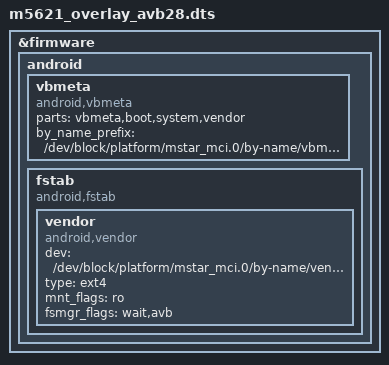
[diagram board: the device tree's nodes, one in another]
/dts-v1/;
/plugin/;

&firmware {
	android {
		vbmeta {
			compatible = "android,vbmeta";
			parts = "vbmeta,boot,system,vendor";
			by_name_prefix ="/dev/block/platform/mstar_mci.0/by-name/vbmeta";
		};
		fstab {
			compatible = "android,fstab";
			vendor {
				compatible = "android,vendor";
				dev = "/dev/block/platform/mstar_mci.0/by-name/vendor";
				type = "ext4";
				mnt_flags = "ro";
				fsmgr_flags = "wait,avb";
			};

		};
	};
};
